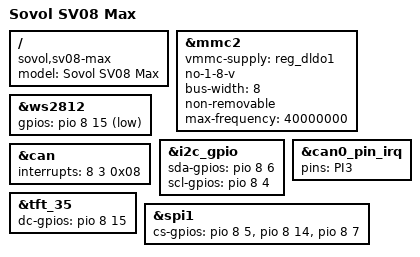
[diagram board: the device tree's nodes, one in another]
// SPDX-License-Identifier: (GPL-2.0+ or MIT)
/*
 * Sovol SV08 Max - Allwinner H616 printer host, a BigTreeTech CB1 clone.
 *
 * Electrically the eMMC-variant CB1, so it reuses the CB1 device tree and
 * u-boot. Board-level differences vs the CB1:
 *   - onboard eMMC part validated by the vendor at 40 MHz (the CB1 device
 *     tree leaves mmc2 at the SoC default);
 *   - a toolboard UART is broken out; enable it with the stock
 *     sun50i-h616-uart4-pi overlay (DEFAULT_OVERLAYS in the board config).
 *
 * Community board: not yet verified on hardware.
 */

/dts-v1/;

#include "sun50i-h616-bigtreetech-cb1.dtsi"

/ {
	model = "Sovol SV08 Max";
	compatible = "sovol,sv08-max", "bigtreetech,cb1", "allwinner,sun50i-h616";
};

&mmc2 {
	vmmc-supply = <&reg_dldo1>;

	no-1-8-v;
	bus-width = <8>;
	non-removable;
	max-frequency = <40000000>;
	status = "okay";
};

&ws2812 {
	gpios = <&pio 8 15 GPIO_ACTIVE_LOW>; /* PI15 */
};

&i2c_gpio {
	sda-gpios = <&pio 8 6 (GPIO_ACTIVE_HIGH | GPIO_OPEN_DRAIN)>; /* PI6 */
	scl-gpios = <&pio 8 4 (GPIO_ACTIVE_HIGH | GPIO_OPEN_DRAIN)>; /* PI4 */
};

&can0_pin_irq {
	pins = "PI3";
};

&can {
	interrupts = <8 3 0x08>; /* PI3 IRQ_TYPE_LEVEL_LOW */
};

&tft_35 {
	dc-gpios  = <&pio 8 15 GPIO_ACTIVE_HIGH>; /* PI15 */
};

&spi1 {
	cs-gpios = <&pio 8 5 GPIO_ACTIVE_HIGH>, /* PI5 */
			   <&pio 8 14 GPIO_ACTIVE_HIGH>, /* PI14 */
			   <&pio 8 7 GPIO_ACTIVE_HIGH>; /* PI7 */
};
